# CY8C5888LTI_LP097 register map
File version: 0.1
CY8C58LP
Registers are 8-bit, read-write, no defined reset value unless marked. A register's access mark holds for its fields unless they carry their own. Offsets are from the block's base; lines under a group give offsets from that group; [hi:lo] are bit positions; {n}, {i} and the like mark numbered series; 'fields as' and 'values as' point back to an identical list; <NAME> marks a mode.

## Memory map
0x00000000 S3_Timer
0x00000000 S2_Timer
0x00000000 Status_Reg_1
0x00000000 I2C
0x00000000 Status_Reg_2
0x00000000 S4_Timer
0x00000000 RobotArm_Servo
0x00000000 UART
0x00000000 QuadDec_L
0x00000000 QuadDec_L_Cnt16
0x00000000 QuadDec_R
0x00000000 QuadDec_R_Cnt16
0x00000000 PWM_Motor
0x00000000 Flicker_Servo
0x00000000 Control_Reg_Color
0x00000000 Color_Timer
0x00000000 Color_Counter
0x00000000 S1_Timer

## S3_Timer
Base 0x00000000
0x40006408 S3_Timer_COUNTER 16-bit — UDB.A0 - Current Down Counter Value
0x40006428 S3_Timer_PERIOD 16-bit — UDB.D0 - Assigned Period
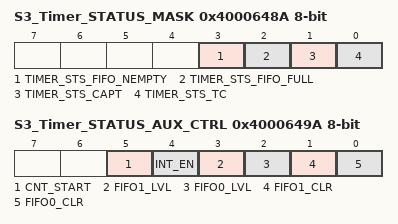
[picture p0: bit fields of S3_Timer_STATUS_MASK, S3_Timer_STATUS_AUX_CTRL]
0x4000648A S3_Timer_STATUS_MASK — UDB Status bits Interrupt Mask Enable Register
  [3] TIMER_STS_FIFO_NEMPTY ro — FIFO Empty status
  [2] TIMER_STS_FIFO_FULL ro — FIFO Full Status
  [1] TIMER_STS_CAPT ro — Enables the Interrupt on Capture
  [0] TIMER_STS_TC ro — Enables the Interrupt on TC
0x4000649A S3_Timer_STATUS_AUX_CTRL — UDB Auxilliary Control Register
  [5] CNT_START — FIFO0 clear
    0=E_CNT_START0 (Disable counter); 1=E_CNT_START1 (Enable counter)
  [4] INT_EN
    0=E_INT_EN0 (Interrupt disabled); 1=E_INT_EN1 (Interrupt enabled)
  [3] FIFO1_LVL — FIFO level
    0=E_FIFO_LVL_0 (FIFO LVL: input mode: FIFO not full; output mode: FIFO not empty); 1=E_FIFO_LVL_1 (FIFO LVL: input mode: FIFO at least 1/2 empty; output mode: FIFO at least 1/2 full)
  [2] FIFO0_LVL — FIFO level
    values as FIFO1_LVL
  [1] FIFO1_CLR — FIFO1 clear
    0=E_FIFO_CLR_0 (Normal FIFO operation); 1=E_FIFO_CLR_1 (Clear FIFO state)
  [0] FIFO0_CLR — FIFO0 clear
    values as FIFO1_CLR

## S2_Timer
Base 0x00000000
0x40006506 S2_Timer_COUNTER 16-bit — UDB.A0 - Current Down Counter Value
0x40006526 S2_Timer_PERIOD 16-bit — UDB.D0 - Assigned Period
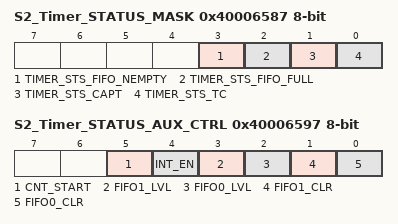
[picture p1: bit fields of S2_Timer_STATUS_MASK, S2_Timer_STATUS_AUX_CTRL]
0x40006587 S2_Timer_STATUS_MASK — UDB Status bits Interrupt Mask Enable Register
  [3] TIMER_STS_FIFO_NEMPTY ro — FIFO Empty status
  [2] TIMER_STS_FIFO_FULL ro — FIFO Full Status
  [1] TIMER_STS_CAPT ro — Enables the Interrupt on Capture
  [0] TIMER_STS_TC ro — Enables the Interrupt on TC
0x40006597 S2_Timer_STATUS_AUX_CTRL — UDB Auxilliary Control Register
  [5] CNT_START — FIFO0 clear
    0=E_CNT_START0 (Disable counter); 1=E_CNT_START1 (Enable counter)
  [4] INT_EN
    0=E_INT_EN0 (Interrupt disabled); 1=E_INT_EN1 (Interrupt enabled)
  [3] FIFO1_LVL — FIFO level
    0=E_FIFO_LVL_0 (FIFO LVL: input mode: FIFO not full; output mode: FIFO not empty); 1=E_FIFO_LVL_1 (FIFO LVL: input mode: FIFO at least 1/2 empty; output mode: FIFO at least 1/2 full)
  [2] FIFO0_LVL — FIFO level
    values as FIFO1_LVL
  [1] FIFO1_CLR — FIFO1 clear
    0=E_FIFO_CLR_0 (Normal FIFO operation); 1=E_FIFO_CLR_1 (Clear FIFO state)
  [0] FIFO0_CLR — FIFO0 clear
    values as FIFO1_CLR

## Status_Reg_1
Base 0x00000000
0x40006564 Status_Reg_1_STATUS_REG
0x40006584 Status_Reg_1_MASK_REG
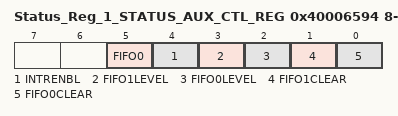
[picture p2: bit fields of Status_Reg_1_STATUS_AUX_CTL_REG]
0x40006594 Status_Reg_1_STATUS_AUX_CTL_REG
  [5] FIFO0 — FIFO0 clear
    1=ENABLED (Enable counter); 0=DISABLED (Disable counter)
  [4] INTRENBL — Enables or disables the Interrupt
    1=ENABLED (Interrupt enabled); 0=DISABLED (Interrupt disabled)
  [3] FIFO1LEVEL — FIFO level
    1=ENABLED (FIFO LVL: input mode: FIFO at least 1/2 empty; output mode: FIFO at least 1/2 full); 0=DISABLED (FIFO LVL: input mode: FIFO not full; output mode: FIFO not empty)
  [2] FIFO0LEVEL — FIFO level
    values as FIFO1LEVEL
  [1] FIFO1CLEAR — FIFO clear
    1=ENABLED (Clear FIFO state); 0=DISABLED (Normal FIFO operation)
  [0] FIFO0CLEAR — FIFO clear
    values as FIFO1CLEAR

## Status_Reg_2
Base 0x00000000
0x40006468 Status_Reg_2_STATUS_REG
0x40006488 Status_Reg_2_MASK_REG
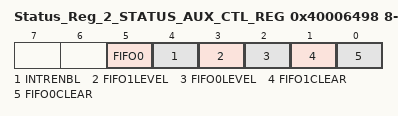
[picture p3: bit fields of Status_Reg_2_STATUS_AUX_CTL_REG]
0x40006498 Status_Reg_2_STATUS_AUX_CTL_REG
  [5] FIFO0 — FIFO0 clear
    1=ENABLED (Enable counter); 0=DISABLED (Disable counter)
  [4] INTRENBL — Enables or disables the Interrupt
    1=ENABLED (Interrupt enabled); 0=DISABLED (Interrupt disabled)
  [3] FIFO1LEVEL — FIFO level
    1=ENABLED (FIFO LVL: input mode: FIFO at least 1/2 empty; output mode: FIFO at least 1/2 full); 0=DISABLED (FIFO LVL: input mode: FIFO not full; output mode: FIFO not empty)
  [2] FIFO0LEVEL — FIFO level
    values as FIFO1LEVEL
  [1] FIFO1CLEAR — FIFO clear
    1=ENABLED (Clear FIFO state); 0=DISABLED (Normal FIFO operation)
  [0] FIFO0CLEAR — FIFO clear
    values as FIFO1CLEAR
